# GD32H7xx register map
File version: 1.0
CPU: CM7 r1p2, little endian, MPU, FPU, 4 interrupt priority bits
Registers are 32-bit, read-write, reset 0x0 unless marked. A register's access mark holds for its fields unless they carry their own. Offsets are from the block's base; [hi:lo] are bit positions; {n}, {i} and the like mark numbered series; 'fields as' and 'values as' point back to an identical list.

## AXI — System and memory architectur
Base 0x51000000
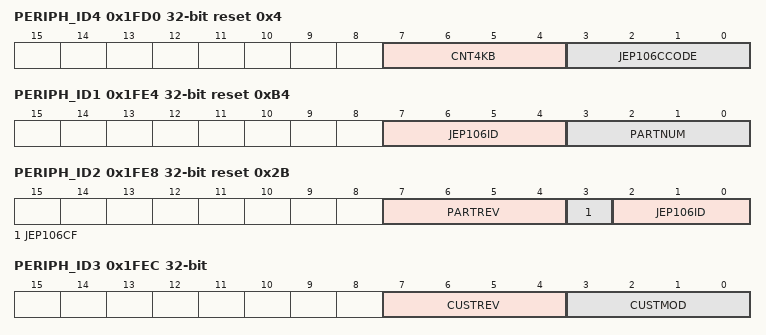
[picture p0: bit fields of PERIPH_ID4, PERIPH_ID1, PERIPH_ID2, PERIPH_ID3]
0x1FD0 PERIPH_ID4 ro reset 0x4 — AXI peripheral ID4 register
  [7:4] CNT4KB — 4KB count
  [3:0] JEP106CCODE — JEP106 continuation code
0x1FE0 PERIPH_ID0 ro — AXI peripheral ID0 register
  [7:0] PARTNUM — Part number[7:0]
0x1FE4 PERIPH_ID1 ro reset 0xB4 — AXI peripheral ID1 register
  [7:4] JEP106ID — JEP106 Identity[3:0]
  [3:0] PARTNUM — Part number[11:8]
0x1FE8 PERIPH_ID2 ro reset 0x2B — AXI peripheral ID2 register
  [7:4] PARTREV — Part revision
  [3] JEP106CF — JEP106 code flag
  [2:0] JEP106ID — Part number[11:8]
0x1FEC PERIPH_ID3 ro — AXI peripheral ID3 register
  [7:4] CUSTREV — Customer version
  [3:0] CUSTMOD — Customer modification
0x1FF0 COMP_ID0 ro reset 0xD — AXI componet ID0 register
  [7:0] PREAMB — Preamble bits
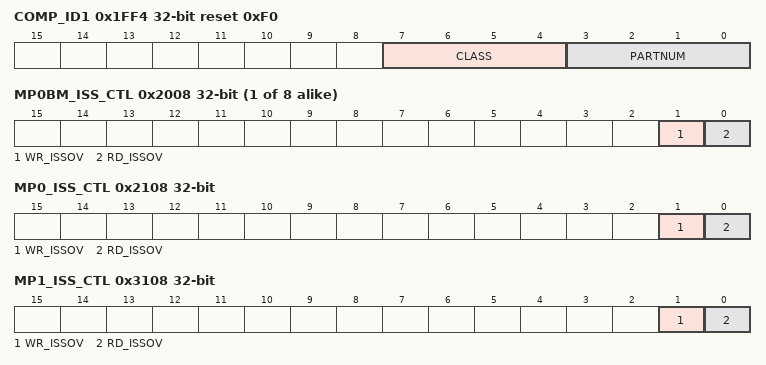
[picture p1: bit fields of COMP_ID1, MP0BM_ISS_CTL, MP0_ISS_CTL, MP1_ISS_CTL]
0x1FF4 COMP_ID1 ro reset 0xF0 — AXI componet ID1 register
  [7:4] CLASS — Component class
  [3:0] PARTNUM — Preamble bits
0x1FF8 COMP_ID2 ro reset 0x5 — AXI componet ID2 register
  [7:0] PREAMB — Preamble bits
0x1FFC COMP_ID3 ro reset 0xB1 — AXI componet ID3 register
  [7:0] PREAMB — Preamble bits
{0x2008+0x1000*i} MP{i}BM_ISS_CTL (i=0..7) — AXI Master Port {i} bus matrix issuing functionality control regist
  [1] WR_ISSOV — Override target write issuing function
  [0] RD_ISSOV — Override target read issuing function
0x2024 MP0BM_CTL — AXI Master Port 0 bus matrix functionality control regist
  [0] BPDIS — Beats packing function disable configure
0x202C MP0_LB_CTL — AXI Master Port 0 long burst functionality control regist
  [0] LBEN — Control long burst function
0x2108 MP0_ISS_CTL — AXI Master Port 0 issuing functionality control regist
  [1] WR_ISSOV — Override AMIB write issuing function
  [0] RD_ISSOV — Override AMIB read issuing function
0x3024 MP1BM_CTL — AXI Master Port 1 bus matrix functionality control regist
  [0] BPDIS — Beats packing function disable configure
0x302C MP1_LB_CTL — AXI Master Port 1 long burst functionality control regist
  [0] LBEN — Control long burst function
0x3108 MP1_ISS_CTL — AXI Master Port 1 issuing functionality control regist
  fields as MP0_ISS_CTL
0x8024 MP6BM_CTL — AXI Master Port 6 bus matrix functionality control regist
  [0] BPDIS — Beats packing function disable configure
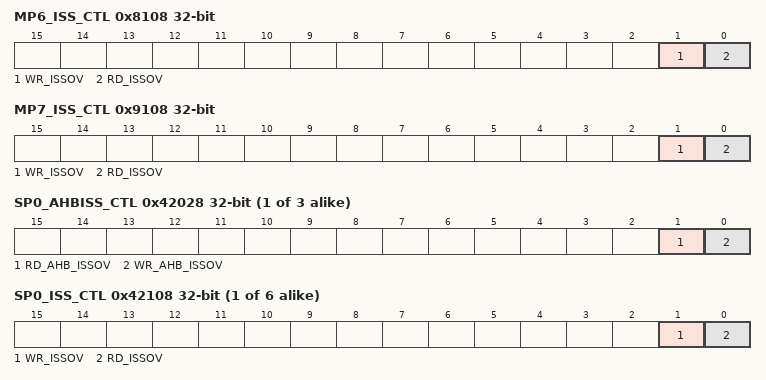
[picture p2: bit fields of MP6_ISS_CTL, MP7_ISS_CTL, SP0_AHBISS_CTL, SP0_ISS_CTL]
0x8108 MP6_ISS_CTL — AXI Master Port 6 issuing functionality control regist
  fields as MP0_ISS_CTL
0x9024 MP7BM_CTL — AXI Master Port 7 bus matrix functionality control regist
  [0] BPDIS — Beats packing function disable configure
0x9108 MP7_ISS_CTL — AXI Master Port 7 issuing functionality control regist
  fields as MP0_ISS_CTL
{0x42024+0x1000*i} SP{i}_CTL (i=0..2) — AXI Slave Port {i} functionality control regist
  [0] TRANSALT — Transaction alteration configure
{0x42028+0x1000*i} SP{i}_AHBISS_CTL (i=0..2) — AXI Slave Port {i} AHB issuing functionality control regist
  [1] RD_AHB_ISSOV — Converts AHB-Lite read transaction to single beat AXI transaction function
  [0] WR_AHB_ISSOV — Converts AHB-Lite write transaction to single beat AXI transaction function
{0x42100+0x1000*i} SP{i}_RDQOS_CTL (i=0..5) — AXI Slave Port {i} read QOS control regist
  [3:0] RDQOS — Read channel QoS configure
{0x42104+0x1000*i} SP{i}_WRQOS_CTL (i=0..5) — AXI Slave Port {i} write QOS control regist
  [3:0] WRQOS — Write channel QoS configure
{0x42108+0x1000*i} SP{i}_ISS_CTL (i=0..5) — AXI Slave Port {i} issuing functionality control regist
  [1] WR_ISSOV — Override ASIB write issuing function
  [0] RD_ISSOV — Override ASIB read issuing function

## CAU — Cryptographic acceleration unit
Base 0x48021000
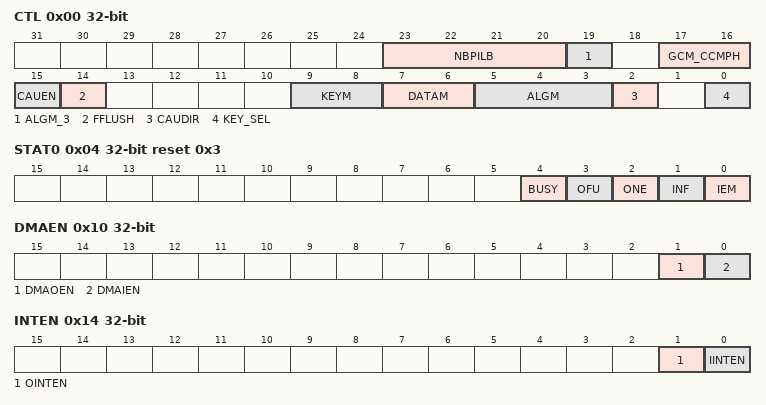
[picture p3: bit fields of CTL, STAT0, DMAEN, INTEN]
0x00 CTL access per field — CAU control register
  [23:20] NBPILB rw — Number of bytes padding in last block of payload
  [19] ALGM_3 rw — Encryption/decryption algorithm mode bit 3
  [17:16] GCM_CCMPH rw — GCM CCM phase
  [15] CAUEN rw — Cryptographic module enable
  [14] FFLUSH wo — FIFO flush
  [9:8] KEYM rw — AES key size mode configuration
  [7:6] DATAM rw — Data swapping type mode configuration
  [5:3] ALGM rw — Encryption/decryption algorithm mode
  [2] CAUDIR rw — CAU direction
  [0] KEY_SEL rw — Key select
0x04 STAT0 ro reset 0x3 — CAU status register 0
  [4] BUSY — BUSY flag
  [3] OFU — OUT FIFO full flag
  [2] ONE — OUT FIFO not empty flag
  [1] INF — IN FIFO not full flag
  [0] IEM — IN FIFO empty flag
0x08 DI — CAU data input register
  [31:0] DI — Data input
0x0C DO ro — CAU data output register
  [31:0] DO — Data output
0x10 DMAEN — CAU DMA enable register
  [1] DMAOEN — Out FIFO DMA enable
  [0] DMAIEN — In FIFO DMA enable
0x14 INTEN — CAU interrupt enable register
  [1] OINTEN — Out FIFO interrupt enable
  [0] IINTEN — In FIFO interrupt enable
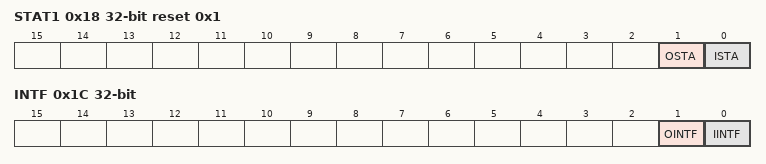
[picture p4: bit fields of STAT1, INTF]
0x18 STAT1 ro reset 0x1 — CAU interrupt status flag register 1
  [1] OSTA — Out FIFO interrupt flag
  [0] ISTA — In FIFO interrupt flag
0x1C INTF ro — CAU enable interrupt status flag register
  [1] OINTF — Out FIFO enabled interrupt flag
  [0] IINTF — In FIFO enabled interrupt flag
{0x20+8i} KEY{i}H wo (i=0..3) — CAU key register
  [31:0] KEY{i}H — Key for DES,TDES,AES
{0x24+8i} KEY{i}L wo (i=0..3) — CAU key register
  [31:0] KEY{i}L — Key for DES,TDES,AES
0x40 IV0H — CAU initialization register
  [31:0] IV0H — The initialization vector for DES,TDES,AES
0x44 IV0L — CAU initialization register
  [31:0] IV0L — The initialization vector for DES,TDES,AES
0x48 IV1H — CAU initialization register
  [31:0] IV1H — The initialization vector for DES,TDES,AES
0x4C IV1L — CAU initialization register
  [31:0] IV1L — The initialization vector for DES,TDES,AES
{0x50+4i} GCMCCMCTXS{i} (i=0..7) — GCM or CCM mode context switch register {i}
  [31:0] CTX{i} — The internal status of the CAU core
{0x70+4i} GCMCTXS{i} (i=0..7) — GCM mode context switch register {i}
  [31:0] CTX{i} — The internal status of the CAU core
